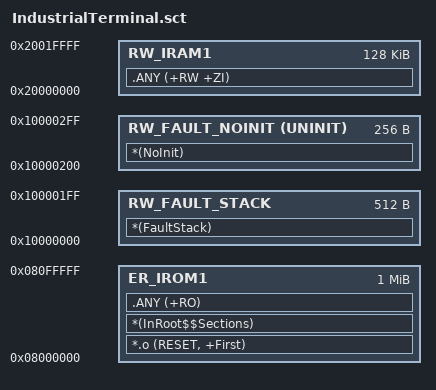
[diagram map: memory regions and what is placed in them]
; *************************************************************
; STM32F407ZG scatter-loading description for IndustrialTerminal
; *************************************************************

LR_IROM1 0x08000000 0x00100000  {
  ER_IROM1 0x08000000 0x00100000  {
    *.o (RESET, +First)
    *(InRoot$$Sections)
    .ANY (+RO)
  }

  RW_FAULT_STACK 0x10000000 0x00000200  {
    *(FaultStack)
  }

  RW_FAULT_NOINIT 0x10000200 UNINIT 0x00000100  {
    *(NoInit)
  }

  RW_IRAM1 0x20000000 0x00020000  {
    .ANY (+RW +ZI)
  }
}
